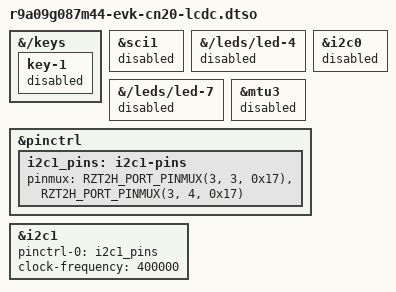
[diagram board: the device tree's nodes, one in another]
// SPDX-License-Identifier: GPL-2.0
/*
 * DT overlay for the RZ/N2H EVK with ADV7513 transmitter
 * connected to DU enabled.
 *
 * Copyright (C) 2026 Renesas Electronics Corp.
 */

/dts-v1/;
/plugin/;

/*
 * RZ/N2H LCDC configuration:
 * ----------------------------------------------------------
 * Function        Pin     SW Setting
 * ----------------------------------------------------------
 * LCDC_DATG0     P11_0, DSW12[3]: ON, DSW12[4]: OFF
 * LCDC_DATG3     P14_3, DSW5[3]: OFF, DSW18[5]: OFF, DSW18[6]: ON
 * LCDC_DATG6     P14_6, DSW15[8]: ON, DSW15[9]: OFF, DSW15[10]: OFF
 * LCDC_DATB2     P18_1, DSW18[9]: OFF, DSW18[10]: ON
 * I2C_SDA1       P03_3, DSW7[1]: ON, DSW7[2]: OFF
 * I2C_SCL1       P03_4, DSW7[3]: ON, DSW7[4]: OFF
 * ------------------------------------------------
 */

#include "rzt2h-n2h-evk-du-adv7513.dtsi"

&{/keys} {
    /* P18_2 is used for DU function LCDC_DATB3. */
    key-1 {
        status = "disabled";
    };
};

&sci1 {
       /* SCI1 shares P18_2 - P18_6 depending on RSCI1_SEL. */
       status = "disabled";
};

&{/leds/led-4} {
	/* P18_1 is used for DU function LCDC_DATB2. */
	status = "disabled";
};

&{/leds/led-7} {
	/* P14_3 is used for DU function LCDC_DATG3. */
	status = "disabled";
};

&i2c0 {
	status = "disabled";
};

&mtu3 {
	status = "disabled";
};

&pinctrl {
	i2c1_pins: i2c1-pins {
		pinmux = <RZT2H_PORT_PINMUX(3, 3, 0x17)>,
			 <RZT2H_PORT_PINMUX(3, 4, 0x17)>;
	};
};

&i2c1 {
	pinctrl-0 = <&i2c1_pins>;
	pinctrl-names = "default";
	clock-frequency = <400000>;
	status = "okay";
};
